AUTOSAR XML (schema 00048)
package /HuaweiMDC/FunctionalSoftware/CameraDetectionApplication/Execution
  executable CameraDetectionExecutable
    root sw component prototype CameraDetectionRootSwComponent: application-type=CameraDetectionApplicationSwComponent
package /HuaweiMDC/FunctionalSoftware/CameraDetectionApplication/SwComponent
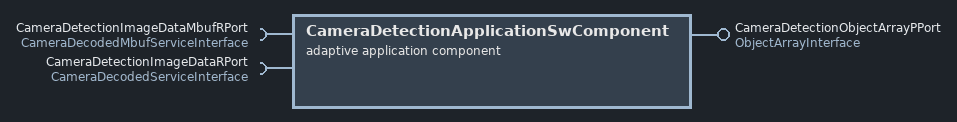
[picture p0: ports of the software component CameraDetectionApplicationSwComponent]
  adaptive application sw component type CameraDetectionApplicationSwComponent
    require port CameraDetectionImageDataMbufRPort: required-interface=CameraDecodedMbufServiceInterface
    provide port CameraDetectionObjectArrayPPort: provided-interface=ObjectArrayInterface
    require port CameraDetectionImageDataRPort: required-interface=CameraDecodedServiceInterface
